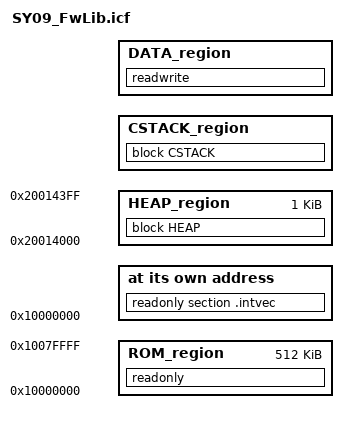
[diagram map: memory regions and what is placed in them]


/* define the memory address symbol */

/*-.intvec start-*/
define symbol __intvec_start__ = 0x10000000;
/*-Memory Regions-*/
define symbol __region_ROM_start__ = 0x10000000;
define symbol __region_ROM_end__   = 0x1007FFFF;

define symbol __region_RAM_start__ = 0x20014000;
define symbol __region_RAM_end__   = 0x2001FFFF; 
//define symbol __region_RAM_end__   = 0x20018BFF;

/*-Sizes-*/
define symbol __size_heap__   = 1K;
define symbol __size_cstack__ = 16K;

/* define the memory space size */
define memory mem with size = 4G;

/* define the region for section */
define region ROM_region   = mem:[from __region_ROM_start__   to __region_ROM_end__];
define region HEAP_region   = mem:[from __region_RAM_start__   size __size_heap__];
define region CSTACK_region   = mem:[from end(HEAP_region)+1   size __size_cstack__];
define region DATA_region   = mem:[from end(CSTACK_region)+1   to __region_RAM_end__];

define block CSTACK    with alignment = 8, size = __size_cstack__   { };
define block HEAP      with alignment = 8, size = __size_heap__     { };

initialize by copy { readwrite };
do not initialize  { section .noinit };

place at address mem:__intvec_start__ { readonly section .intvec };

place in ROM_region   { readonly };
place in HEAP_region  { block HEAP};
place in CSTACK_region  { block CSTACK};
place in DATA_region  { readwrite};



